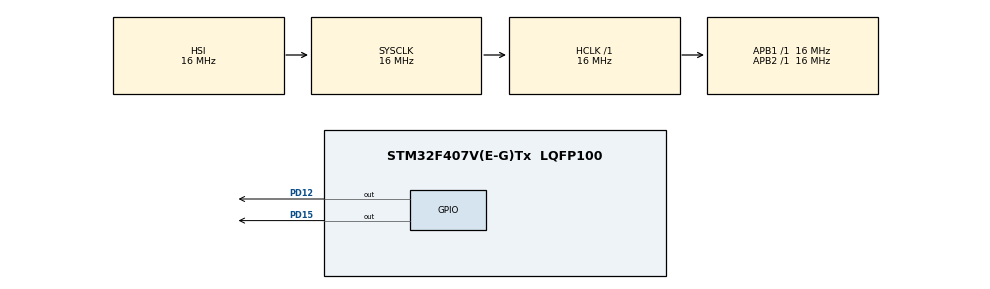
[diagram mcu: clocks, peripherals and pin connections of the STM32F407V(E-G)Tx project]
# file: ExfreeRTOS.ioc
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Mcu.Family=STM32F4
RCC.CortexFreq_Value=16000000
FREERTOS.Tasks01=defaultTask,0,128,StartDefaultTask,Default,NULL,Dynamic,NULL,NULL;ledazul1,0,128,Startledazul1,Default,NULL,Dynamic,NULL,NULL;ledverde2,0,128,Startledverde2,Default,NULL,Dynamic,NULL,NULL
ProjectManager.StackSize=0x400
ProjectManager.TargetToolchain=STM32CubeIDE
RCC.LSE_VALUE=32768
RCC.AHBFreq_Value=16000000
RCC.HSE_VALUE=25000000
board=custom
RCC.VCOOutputFreq_Value=192000000
RCC.APB2Freq_Value=16000000
VP_FREERTOS_VS_CMSIS_V1.Mode=CMSIS_V1
Mcu.Name=STM32F407V(E-G)Tx
RCC.SYSCLKFreq_VALUE=16000000
Mcu.Package=LQFP100
PD12.Signal=GPIO_Output
ProjectManager.HeapSize=0x200
RCC.HSI_VALUE=16000000
NVIC.PriorityGroup=NVIC_PRIORITYGROUP_4
RCC.APB1Freq_Value=16000000
PD15.Signal=GPIO_Output

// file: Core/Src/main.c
/* USER CODE BEGIN Header */
/**
  ******************************************************************************
  * @file           : main.c
  * @brief          : Main program body
  ******************************************************************************
  * @attention
  *
  * <h2><center>&copy; Copyright (c) 2022 STMicroelectronics.
  * All rights reserved.</center></h2>
  *
  * This software component is licensed by ST under BSD 3-Clause license,
  * the "License"; You may not use this file except in compliance with the
  * License. You may obtain a copy of the License at:
  *                        opensource.org/licenses/BSD-3-Clause
  *
  ******************************************************************************
  */
/* USER CODE END Header */
#include "main.h"
#include "cmsis_os.h"

osThreadId defaultTaskHandle;
osThreadId ledazul1Handle;
osThreadId ledverde2Handle;

void SystemClock_Config(void);
static void MX_GPIO_Init(void);
void StartDefaultTask(void const * argument);
void Startledazul1(void const * argument);
void Startledverde2(void const * argument);

int main(void)
{

  /* MCU Configuration--------------------------------------------------------*/

  /* Reset of all peripherals, Initializes the Flash interface and the Systick. */
  HAL_Init();

  /* Configure the system clock */
  SystemClock_Config();

  /* Initialize all configured peripherals */
  MX_GPIO_Init();

  /* Create the thread(s) */
  /* definition and creation of defaultTask */
  osThreadDef(defaultTask, StartDefaultTask, osPriorityNormal, 0, 128);
  defaultTaskHandle = osThreadCreate(osThread(defaultTask), NULL);

  /* definition and creation of ledazul1 */
  osThreadDef(ledazul1, Startledazul1, osPriorityNormal, 0, 128);
  ledazul1Handle = osThreadCreate(osThread(ledazul1), NULL);

  /* definition and creation of ledverde2 */
  osThreadDef(ledverde2, Startledverde2, osPriorityNormal, 0, 128);
  ledverde2Handle = osThreadCreate(osThread(ledverde2), NULL);

  /* Start scheduler */
  osKernelStart();

  /* We should never get here as control is now taken by the scheduler */
  /* Infinite loop */
  while (1)
  {

  }
}

void SystemClock_Config(void)
{
  RCC_OscInitTypeDef RCC_OscInitStruct = {0};
  RCC_ClkInitTypeDef RCC_ClkInitStruct = {0};

  /** Configure the main internal regulator output voltage
  */
  __HAL_RCC_PWR_CLK_ENABLE();
  __HAL_PWR_VOLTAGESCALING_CONFIG(PWR_REGULATOR_VOLTAGE_SCALE1);
  /** Initializes the RCC Oscillators according to the specified parameters
  * in the RCC_OscInitTypeDef structure.
  */
  RCC_OscInitStruct.OscillatorType = RCC_OSCILLATORTYPE_HSI;
  RCC_OscInitStruct.HSIState = RCC_HSI_ON;
  RCC_OscInitStruct.HSICalibrationValue = RCC_HSICALIBRATION_DEFAULT;
  RCC_OscInitStruct.PLL.PLLState = RCC_PLL_NONE;
  if (HAL_RCC_OscConfig(&RCC_OscInitStruct) != HAL_OK)
  {
    Error_Handler();
  }
  /** Initializes the CPU, AHB and APB buses clocks
  */
  RCC_ClkInitStruct.ClockType = RCC_CLOCKTYPE_HCLK|RCC_CLOCKTYPE_SYSCLK
                              |RCC_CLOCKTYPE_PCLK1|RCC_CLOCKTYPE_PCLK2;
  RCC_ClkInitStruct.SYSCLKSource = RCC_SYSCLKSOURCE_HSI;
  RCC_ClkInitStruct.AHBCLKDivider = RCC_SYSCLK_DIV1;
  RCC_ClkInitStruct.APB1CLKDivider = RCC_HCLK_DIV1;
  RCC_ClkInitStruct.APB2CLKDivider = RCC_HCLK_DIV1;

  if (HAL_RCC_ClockConfig(&RCC_ClkInitStruct, FLASH_LATENCY_0) != HAL_OK)
  {
    Error_Handler();
  }
}

static void MX_GPIO_Init(void)
{
  GPIO_InitTypeDef GPIO_InitStruct = {0};

  /* GPIO Ports Clock Enable */
  __HAL_RCC_GPIOD_CLK_ENABLE();

  /*Configure GPIO pin Output Level */
  HAL_GPIO_WritePin(GPIOD, GPIO_PIN_12|GPIO_PIN_15, GPIO_PIN_RESET);

  /*Configure GPIO pins : PD12 PD15 */
  GPIO_InitStruct.Pin = GPIO_PIN_12|GPIO_PIN_15;
  GPIO_InitStruct.Mode = GPIO_MODE_OUTPUT_PP;
  GPIO_InitStruct.Pull = GPIO_NOPULL;
  GPIO_InitStruct.Speed = GPIO_SPEED_FREQ_LOW;
  HAL_GPIO_Init(GPIOD, &GPIO_InitStruct);

}

void StartDefaultTask(void const * argument)
{
  for(;;)
  {
    osDelay(1);
  }
}

void Startledazul1(void const * argument)
{
  /* USER CODE BEGIN Startledazul1 */
  /* Infinite loop */
  for(;;)
  {
	  HAL_GPIO_TogglePin(GPIOD, GPIO_PIN_15);
	  osDelay(250);  }
  /* USER CODE END Startledazul1 */
}

void Startledverde2(void const * argument)
{
  /* USER CODE BEGIN Startledverde2 */
  /* Infinite loop */
  for(;;)
  {
	  HAL_GPIO_TogglePin(GPIOD, GPIO_PIN_12);
	  osDelay(500);
  }
  /* USER CODE END Startledverde2 */
}

void Error_Handler(void)
{
  __disable_irq();
  while (1)
  {
  }
}

/************************ (C) COPYRIGHT STMicroelectronics *****END OF FILE****/
